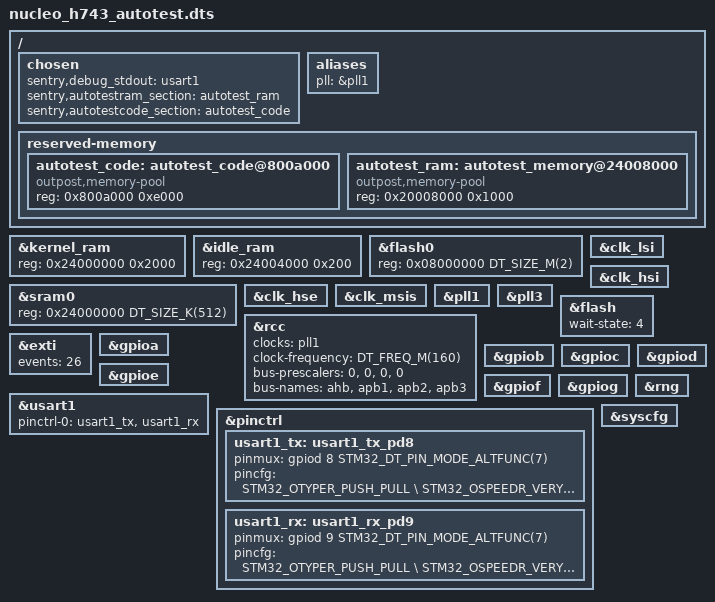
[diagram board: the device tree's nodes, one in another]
/dts-v1/;

#include <st/h7/stm32h743.dtsi>
#include <dt-bindings/pinctrl/stm32-pinctrl.h>
#include <sentry.dtsi>

/{
	chosen {
		sentry,debug_stdout = <&usart1>;
		sentry,autotestram_section = <&autotest_ram>;
		sentry,autotestcode_section = <&autotest_code>;
	};

	aliases {
        pll = &pll1;
    };
};

/{
	reserved-memory {
		autotest_code: autotest_code@800a000 {
			reg = <0x800a000 0xe000>;
			compatible = "outpost,memory-pool";
		};

		autotest_ram: autotest_memory@24008000 {
			reg = <0x20008000 0x1000>;
			compatible = "outpost,memory-pool";
		};


    };

};

&kernel_ram {
	reg = <0x24000000 0x2000>;
};

&idle_ram {
	reg = <0x24004000 0x200>;
};

&flash0 {
	reg = <0x08000000 DT_SIZE_M(2)>;
};

&sram0 {
	reg = <0x24000000 DT_SIZE_K(512)>;
};

&clk_lsi {
	status = "okay";
};

&clk_hsi {
	status = "okay";
};

&clk_hse {
	status = "okay";
};

&clk_msis {
	status = "okay";
};

&pll1 {
	status = "okay";
};

&pll3 {
	status = "okay";
};

&flash {
	wait-state = <4>; /* According to voltage supply and sysclock */
	status = "okay";
};

&rcc {
	clocks = <&pll1>;
	clock-frequency = <DT_FREQ_M(160)>;
	bus-prescalers = <0>, <0>, <0>, <0>;
	bus-names = "ahb", "apb1", "apb2", "apb3";
	status = "okay";
};

&exti {
	events = <26>;
	status = "okay";
};

&gpioa {
	status = "okay";
};

&gpiob {
	status = "okay";
};

&gpioc {
	status = "okay";
};

&gpiod {
	status = "okay";
};

&gpioe {
	status = "okay";
};

&gpiof {
	status = "okay";
};

&gpiog {
	status = "okay";
};

&usart1{
	status = "okay";
	pinctrl-0 = <&usart1_tx>, <&usart1_rx>;
};

&pinctrl {
	usart1_tx: usart1_tx_pd8  {
		pinmux = <&gpiod 8 STM32_DT_PIN_MODE_ALTFUNC(7)>;
		pincfg = <STM32_OTYPER_PUSH_PULL \
				  STM32_OSPEEDR_VERY_HIGH_SPEED \
				  STM32_PUPDR_NO_PULL>;
	};

	usart1_rx: usart1_rx_pd9  {
		pinmux = <&gpiod 9 STM32_DT_PIN_MODE_ALTFUNC(7)>;
		pincfg = <STM32_OTYPER_PUSH_PULL \
				  STM32_OSPEEDR_VERY_HIGH_SPEED \
				  STM32_PUPDR_NO_PULL>;
	};

};

&rng {
	status = "okay";
};

&syscfg {
	status = "okay";
};
